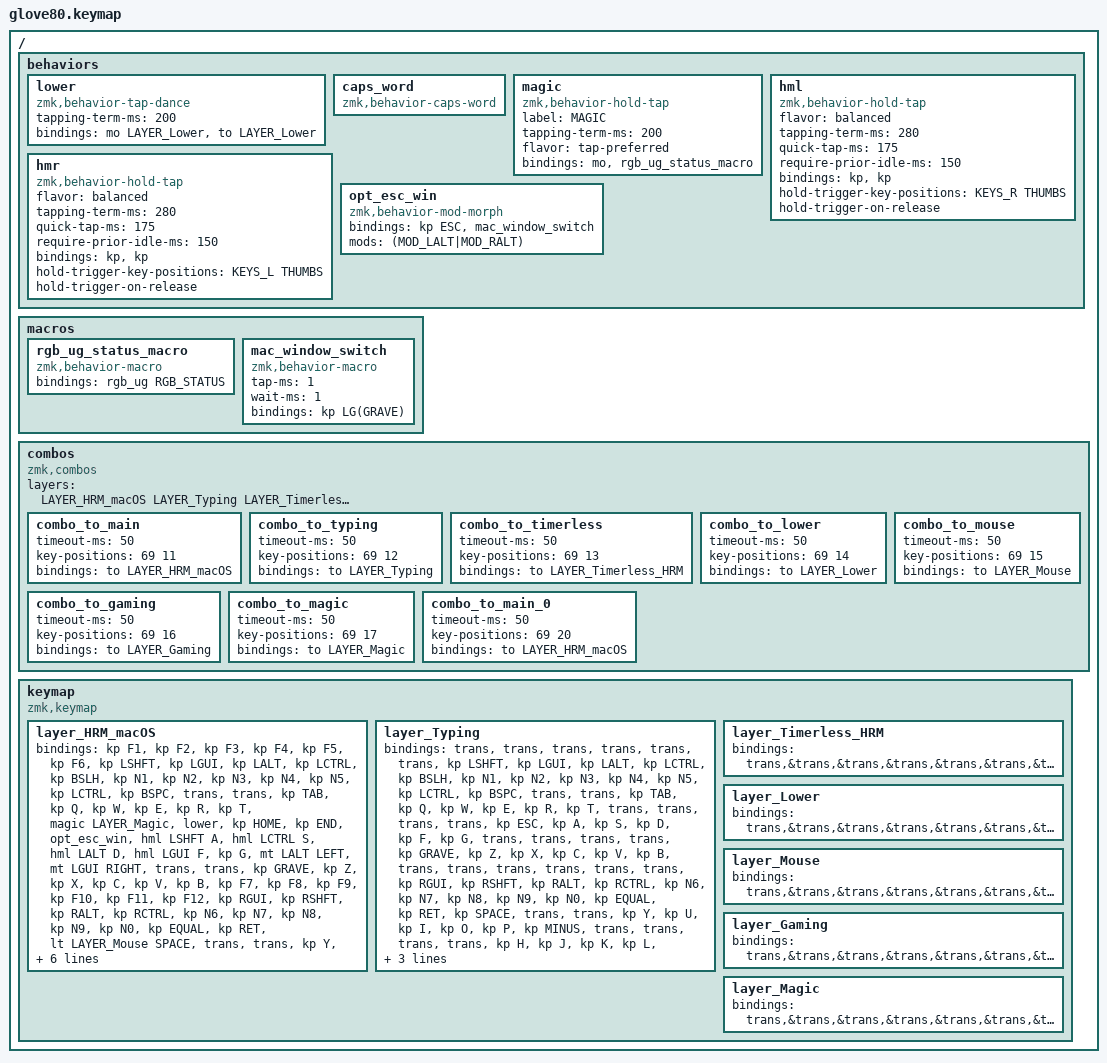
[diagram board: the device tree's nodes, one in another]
/*
==============================================================================
|                                                                            |
|                             Glove80 ZMK Keymap                             |
|                                                                            |
==============================================================================
*/

#include <behaviors.dtsi>
#include <dt-bindings/zmk/outputs.h>
#include <dt-bindings/zmk/keys.h>
#include <dt-bindings/zmk/bt.h>
#include <dt-bindings/zmk/rgb.h>
#include <dt-bindings/zmk/mouse.h>

// Layer Definitions
#define LAYER_HRM_macOS 0
#define LAYER_Typing 1
#define LAYER_Timerless_HRM 2
#define LAYER_Lower 3
#define LAYER_Mouse 4
#define LAYER_Gaming 5
#define LAYER_Magic 6

// Key Position Definitions for Bilateral Home-Row Mods
#define KEYS_L 0 1 2 3 4 5 10 11 12 13 14 15 20 21 22 23 24 25 30 31 32 33 34 35 36 37 38 39
#define KEYS_R 40 41 42 43 44 45 50 51 52 53 54 55 60 61 62 63 64 65 70 71 72 73 74 75 76 77 78 79
#define THUMBS 6 7 8 9 16 17 18 19 26 27 28 29 46 47 48 49 56 57 58 59 66 67 68 69

/ {
    behaviors {
        lower: lower { compatible = "zmk,behavior-tap-dance"; #binding-cells = <0>; tapping-term-ms = <200>; bindings = <&mo LAYER_Lower>, <&to LAYER_Lower>; };
        caps_word: caps_word { compatible = "zmk,behavior-caps-word"; #binding-cells = <0>; };
        magic: magic { compatible = "zmk,behavior-hold-tap"; label = "MAGIC"; #binding-cells = <1>; tapping-term-ms = <200>; flavor = "tap-preferred"; bindings = <&mo>, <&rgb_ug_status_macro>; };
        hml: hml { compatible = "zmk,behavior-hold-tap"; #binding-cells = <2>; flavor = "balanced"; tapping-term-ms = <280>; quick-tap-ms = <175>; require-prior-idle-ms = <150>; bindings = <&kp>, <&kp>; hold-trigger-key-positions = <KEYS_R THUMBS>; hold-trigger-on-release; };
        hmr: hmr { compatible = "zmk,behavior-hold-tap"; #binding-cells = <2>; flavor = "balanced"; tapping-term-ms = <280>; quick-tap-ms = <175>; require-prior-idle-ms = <150>; bindings = <&kp>, <&kp>; hold-trigger-key-positions = <KEYS_L THUMBS>; hold-trigger-on-release; };
        opt_esc_win: opt_esc_win { compatible = "zmk,behavior-mod-morph"; #binding-cells = <0>; bindings = <&kp ESC>, <&mac_window_switch>; mods = <(MOD_LALT|MOD_RALT)>; };
    };

    macros {
        rgb_ug_status_macro: rgb_ug_status_macro { compatible = "zmk,behavior-macro"; #binding-cells = <0>; bindings = <&rgb_ug RGB_STATUS>; };
        mac_window_switch: mac_window_switch { compatible = "zmk,behavior-macro"; #binding-cells = <0>; tap-ms = <1>; wait-ms = <1>; bindings = <&kp LG(GRAVE)>; };
    };

    combos {
        compatible = "zmk,combos";
        layers = <LAYER_HRM_macOS LAYER_Typing LAYER_Timerless_HRM LAYER_Lower LAYER_Mouse LAYER_Gaming LAYER_Magic>;
        combo_to_main { timeout-ms = <50>; key-positions = <69 11>; bindings = <&to LAYER_HRM_macOS>; };
        combo_to_typing { timeout-ms = <50>; key-positions = <69 12>; bindings = <&to LAYER_Typing>; };
        combo_to_timerless { timeout-ms = <50>; key-positions = <69 13>; bindings = <&to LAYER_Timerless_HRM>; };
        combo_to_lower { timeout-ms = <50>; key-positions = <69 14>; bindings = <&to LAYER_Lower>; };
        combo_to_mouse { timeout-ms = <50>; key-positions = <69 15>; bindings = <&to LAYER_Mouse>; };
        combo_to_gaming { timeout-ms = <50>; key-positions = <69 16>; bindings = <&to LAYER_Gaming>; };
        combo_to_magic { timeout-ms = <50>; key-positions = <69 17>; bindings = <&to LAYER_Magic>; };
        combo_to_main_0 { timeout-ms = <50>; key-positions = <69 20>; bindings = <&to LAYER_HRM_macOS>; };
    };

    keymap {
        compatible = "zmk,keymap";

        // FINAL FIX: All layers are now structured with exactly 80 keys (40 per hand),
        // matching the Glove80 hardware definition. This resolves the final build error.
        layer_HRM_macOS {
            bindings = <
            //-----------------------------------------------------  LEFT HAND (40 keys)  -----------------------------------------------------
            &kp F1          &kp F2          &kp F3          &kp F4          &kp F5          &kp F6              &kp LSHFT       &kp LGUI        &kp LALT        &kp LCTRL
            &kp BSLH        &kp N1          &kp N2          &kp N3          &kp N4          &kp N5              &kp LCTRL       &kp BSPC        &trans          &trans
            &kp TAB         &kp Q           &kp W           &kp E           &kp R           &kp T               &magic LAYER_Magic &lower      &kp HOME        &kp END
            &opt_esc_win    &hml LSHFT A    &hml LCTRL S    &hml LALT D     &hml LGUI F     &kp G               &mt LALT LEFT   &mt LGUI RIGHT  &trans          &trans
            &kp GRAVE       &kp Z           &kp X           &kp C           &kp V           &kp B
            //-----------------------------------------------------  RIGHT HAND (40 keys)  ----------------------------------------------------
            &kp F7          &kp F8          &kp F9          &kp F10         &kp F11         &kp F12             &kp RGUI        &kp RSHFT       &kp RALT        &kp RCTRL
            &kp N6          &kp N7          &kp N8          &kp N9          &kp N0          &kp EQUAL           &kp RET         &lt LAYER_Mouse SPACE &trans      &trans
            &kp Y           &kp U           &kp I           &kp O           &kp P           &kp MINUS           &mt RGUI UP     &mt RALT DOWN   &kp LBKT        &kp RBKT
            &kp H           &hmr RGUI J     &hmr LALT K     &hmr RCTRL L    &hmr RSHFT SEMI &kp SQT             &kp PG_DN       &trans          &trans          &trans
            &kp N           &kp M           &kp COMMA       &kp DOT         &kp FSLH        &kp PG_UP
            >;
        };

        layer_Typing {
            bindings = <
            //-----------------------------------------------------  LEFT HAND (40 keys)  -----------------------------------------------------
            &trans          &trans          &trans          &trans          &trans          &trans              &kp LSHFT       &kp LGUI        &kp LALT        &kp LCTRL
            &kp BSLH        &kp N1          &kp N2          &kp N3          &kp N4          &kp N5              &kp LCTRL       &kp BSPC        &trans          &trans
            &kp TAB         &kp Q           &kp W           &kp E           &kp R           &kp T               &trans          &trans          &trans          &trans
            &kp ESC         &kp A           &kp S           &kp D           &kp F           &kp G               &trans          &trans          &trans          &trans
            &kp GRAVE       &kp Z           &kp X           &kp C           &kp V           &kp B
            //-----------------------------------------------------  RIGHT HAND (40 keys)  ----------------------------------------------------
            &trans          &trans          &trans          &trans          &trans          &trans              &kp RGUI        &kp RSHFT       &kp RALT        &kp RCTRL
            &kp N6          &kp N7          &kp N8          &kp N9          &kp N0          &kp EQUAL           &kp RET         &kp SPACE       &trans          &trans
            &kp Y           &kp U           &kp I           &kp O           &kp P           &kp MINUS           &trans          &trans          &trans          &trans
            &kp H           &kp J           &kp K           &kp L           &kp SEMI        &kp SQT             &trans          &trans          &trans          &trans
            &kp N           &kp M           &kp COMMA       &kp DOT         &kp FSLH        &kp PG_UP
            >;
        };

        // All other layers are filled with 80 transparent bindings to ensure they compile.
        layer_Timerless_HRM { bindings = < &trans,&trans,&trans,&trans,&trans,&trans,&trans,&trans,&trans,&trans,&trans,&trans,&trans,&trans,&trans,&trans,&trans,&trans,&trans,&trans,&trans,&trans,&trans,&trans,&trans,&trans,&trans,&trans,&trans,&trans,&trans,&trans,&trans,&trans,&trans,&trans,&trans,&trans,&trans,&trans,&trans,&trans,&trans,&trans,&trans,&trans,&trans,&trans,&trans,&trans,&trans,&trans,&trans,&trans,&trans,&trans,&trans,&trans,&trans,&trans,&trans,&trans,&trans,&trans,&trans,&trans,&trans,&trans,&trans,&trans,&trans,&trans,&trans,&trans,&trans,&trans,&trans,&trans,&trans,&trans >; };
        layer_Lower { bindings = < &trans,&trans,&trans,&trans,&trans,&trans,&trans,&trans,&trans,&trans,&trans,&trans,&trans,&trans,&trans,&trans,&trans,&trans,&trans,&trans,&trans,&trans,&trans,&trans,&trans,&trans,&trans,&trans,&trans,&trans,&trans,&trans,&trans,&trans,&trans,&trans,&trans,&trans,&trans,&trans,&trans,&trans,&trans,&trans,&trans,&trans,&trans,&trans,&trans,&trans,&trans,&trans,&trans,&trans,&trans,&trans,&trans,&trans,&trans,&trans,&trans,&trans,&trans,&trans,&trans,&trans,&trans,&trans,&trans,&trans,&trans,&trans,&trans,&trans,&trans,&trans,&trans,&trans,&trans,&trans >; };
        layer_Mouse { bindings = < &trans,&trans,&trans,&trans,&trans,&trans,&trans,&trans,&trans,&trans,&trans,&trans,&trans,&trans,&trans,&trans,&trans,&trans,&trans,&trans,&trans,&trans,&trans,&trans,&trans,&trans,&trans,&trans,&trans,&trans,&trans,&trans,&trans,&trans,&trans,&trans,&trans,&trans,&trans,&trans,&trans,&trans,&trans,&trans,&trans,&trans,&trans,&trans,&trans,&trans,&trans,&trans,&trans,&trans,&trans,&trans,&trans,&trans,&trans,&trans,&trans,&trans,&trans,&trans,&trans,&trans,&trans,&trans,&trans,&trans,&trans,&trans,&trans,&trans,&trans,&trans,&trans,&trans,&trans,&trans >; };
        layer_Gaming { bindings = < &trans,&trans,&trans,&trans,&trans,&trans,&trans,&trans,&trans,&trans,&trans,&trans,&trans,&trans,&trans,&trans,&trans,&trans,&trans,&trans,&trans,&trans,&trans,&trans,&trans,&trans,&trans,&trans,&trans,&trans,&trans,&trans,&trans,&trans,&trans,&trans,&trans,&trans,&trans,&trans,&trans,&trans,&trans,&trans,&trans,&trans,&trans,&trans,&trans,&trans,&trans,&trans,&trans,&trans,&trans,&trans,&trans,&trans,&trans,&trans,&trans,&trans,&trans,&trans,&trans,&trans,&trans,&trans,&trans,&trans,&trans,&trans,&trans,&trans,&trans,&trans,&trans,&trans,&trans,&trans >; };
        layer_Magic { bindings = < &trans,&trans,&trans,&trans,&trans,&trans,&trans,&trans,&trans,&trans,&trans,&trans,&trans,&trans,&trans,&trans,&trans,&trans,&trans,&trans,&trans,&trans,&trans,&trans,&trans,&trans,&trans,&trans,&trans,&trans,&trans,&trans,&trans,&trans,&trans,&trans,&trans,&trans,&trans,&trans,&trans,&trans,&trans,&trans,&trans,&trans,&trans,&trans,&trans,&trans,&trans,&trans,&trans,&trans,&trans,&trans,&trans,&trans,&trans,&trans,&trans,&trans,&trans,&trans,&trans,&trans,&trans,&trans,&trans,&trans,&trans,&trans,&trans,&trans,&trans,&trans,&trans,&trans,&trans,&trans >; };
    };
};
